# PY32F403xx register map
Vendor: PUYA Co.Ltd; Series: ARMCM4; File version: 1.2
CPU: CM4 r0p1, little endian, MPU, FPU, 4 interrupt priority bits
Registers are 32-bit, read-write, reset 0x0 unless marked. A register's access mark holds for its fields unless they carry their own. Offsets are from the block's base; [hi:lo] are bit positions; {n}, {i} and the like mark numbered series.

## EXTI
Base 0x40010400
0x00 IMR
  [18:0] MR
0x04 EMR
  [18:0] MR
0x08 RTSR
  [18:0] TR
0x0C FTSR
  [18:0] TR
0x10 SWIER
  [18:0] SWIER
0x14 PR
  [18:0] PR

## FLASH
Base 0x40022000
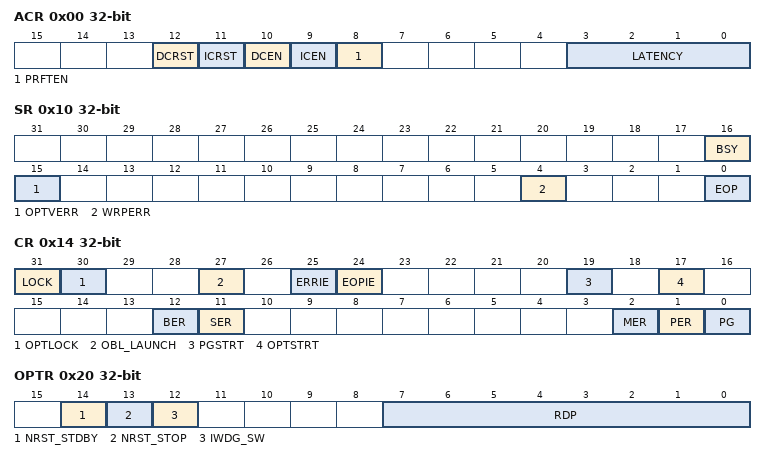
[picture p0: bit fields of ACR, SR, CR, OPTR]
0x00 ACR
  [12] DCRST
  [11] ICRST
  [10] DCEN
  [9] ICEN
  [8] PRFTEN
  [3:0] LATENCY
    1=0; 2=1; 4=2; 8=3
0x08 KEYR
  [31:0] KEY
0x0C OPTKEYR
  [31:0] OPTKEY
0x10 SR
  [16] BSY ro, [15] OPTVERR, [4] WRPERR, [0] EOP
0x14 CR
  [31] LOCK, [30] OPTLOCK, [27] OBL_LAUNCH, [25] ERRIE, [24] EOPIE, [19] PGSTRT, [17] OPTSTRT, [12] BER, [11] SER, [2] MER, [1] PER, [0] PG
0x20 OPTR
  [14] NRST_STDBY, [13] NRST_STOP, [12] IWDG_SW, [7:0] RDP
0x2C WRPR
  [11:0] WRP
    1=0; 2=1; 4=2; 8=3; 16=4; 32=5; 64=6; 128=7; 0x100=8; 0x200=9; 0x400=10; 0x800=11

## GPIOA — desc GPIO
Base 0x48000000
Same registers: GPIOB 0x48000400, GPIOC 0x48000800, GPIOD 0x48000C00, GPIOE 0x48001000
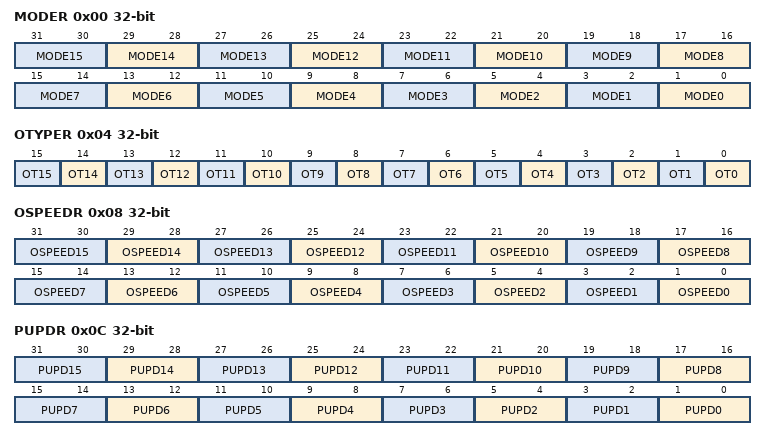
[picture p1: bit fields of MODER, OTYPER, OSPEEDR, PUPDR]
0x00 MODER
  [all] fields
    1=0; 2=1
  [2n+1:2n] MODE{n} (n=0..15)
0x04 OTYPER
  [n] OT{n} (n=0..15)
0x08 OSPEEDR
  [all] fields
    1=0; 2=1
  [2n+1:2n] OSPEED{n} (n=0..15)
0x0C PUPDR
  [all] fields
    1=0; 2=1
  [2n+1:2n] PUPD{n} (n=0..15)
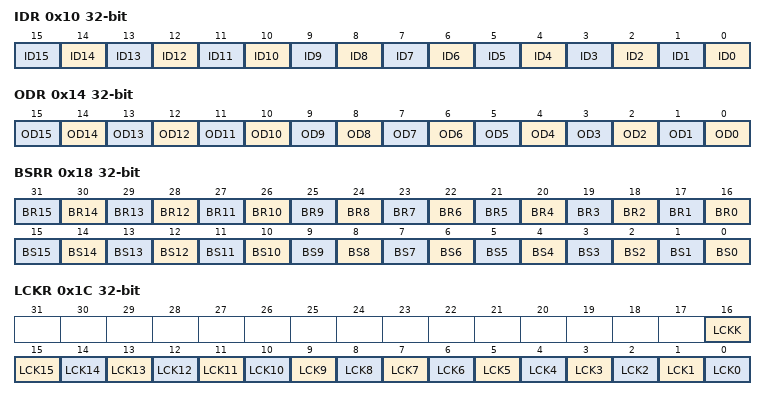
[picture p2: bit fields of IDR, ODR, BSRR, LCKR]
0x10 IDR
  [n] ID{n} ro (n=0..15)
0x14 ODR
  [n] OD{n} (n=0..15)
0x18 BSRR
  [n+16] BR{n} (n=0..15), [n] BS{n} (n=0..15)
0x1C LCKR
  [16] LCKK, [n] LCK{n} (n=0..15)
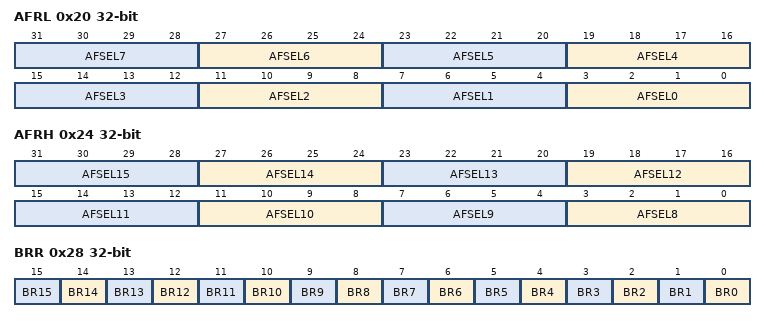
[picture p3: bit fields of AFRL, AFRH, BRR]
0x20 AFRL
  [all] fields
    1=0; 2=1; 4=2; 8=3
  [4n+3:4n] AFSEL{n} (n=0..7)
0x24 AFRH
  [all] fields
    1=0; 2=1; 4=2; 8=3
  [4n-29:4n-32] AFSEL{n} (n=8..15)
0x28 BRR
  [n] BR{n} (n=0..15)

## I2C1 — desc I2C
Base 0x40005400
Same registers: I2C2 0x40005800
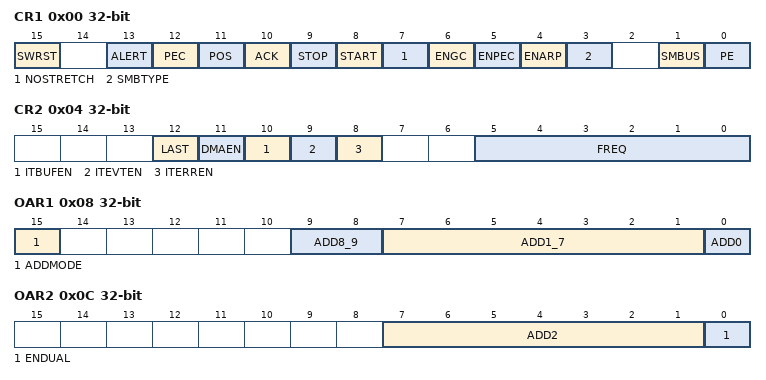
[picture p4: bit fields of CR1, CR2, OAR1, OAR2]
0x00 CR1
  [15] SWRST, [13] ALERT, [12] PEC, [11] POS, [10] ACK, [9] STOP, [8] START, [7] NOSTRETCH, [6] ENGC, [5] ENPEC, [4] ENARP, [3] SMBTYPE, [1] SMBUS, [0] PE
0x04 CR2
  [12] LAST
  [11] DMAEN
  [10] ITBUFEN
  [9] ITEVTEN
  [8] ITERREN
  [5:0] FREQ
    1=0; 2=1; 4=2; 8=3; 16=4; 32=5
0x08 OAR1
  [15] ADDMODE
  [9:8] ADD8_9 — desc ADD
  [7:1] ADD1_7 — desc ADD
  [0] ADD0
0x0C OAR2
  [7:1] ADD2, [0] ENDUAL
0x10 DR
  [7:0] DR
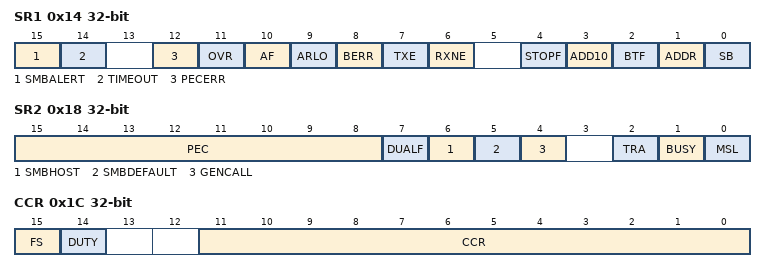
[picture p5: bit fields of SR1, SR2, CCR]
0x14 SR1
  [15] SMBALERT, [14] TIMEOUT, [12] PECERR, [11] OVR, [10] AF, [9] ARLO, [8] BERR, [7] TXE ro, [6] RXNE ro, [4] STOPF ro, [3] ADD10 ro, [2] BTF ro, [1] ADDR ro, [0] SB ro
0x18 SR2
  [15:8] PEC ro, [7] DUALF ro, [6] SMBHOST ro, [5] SMBDEFAULT ro, [4] GENCALL ro, [2] TRA ro, [1] BUSY ro, [0] MSL ro
0x1C CCR
  [15] FS, [14] DUTY, [11:0] CCR
0x20 TRISE
  [5:0] TRISE

## IWDG
Base 0x40003000
0x00 KR
  [15:0] KEY
0x04 PR
  [2:0] PR
    1=0; 2=1; 4=2
0x08 RLR
  [11:0] RL
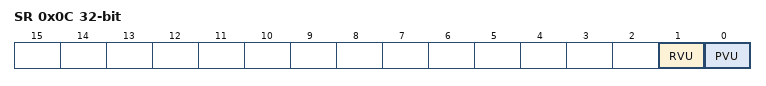
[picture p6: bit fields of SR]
0x0C SR
  [1] RVU ro, [0] PVU ro

## PWR
Base 0x40007000
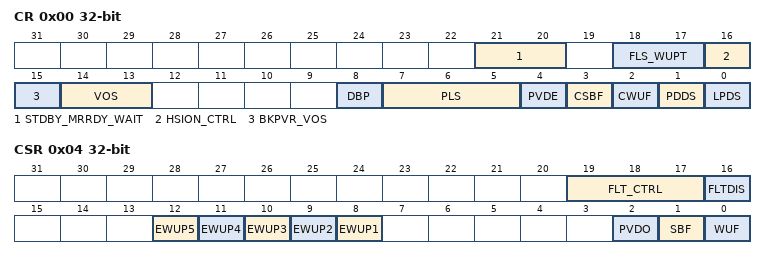
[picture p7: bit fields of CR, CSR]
0x00 CR
  [21:20] STDBY_MRRDY_WAIT
    1=0; 2=1
  [18:17] FLS_WUPT
    1=0; 2=1
  [16] HSION_CTRL
  [15] BKPVR_VOS
  [14:13] VOS
    1=0; 2=1
  [8] DBP
  [7:5] PLS
    0=1V8; 0=LEV0 (PVD level 1.8V); 1=0; 1=2V0; 1=LEV1 (PVD level 2.0V); 2=1; 2=2V2; 2=LEV2 (PVD level 2.2V); 3=2V4; 3=LEV3 (PVD level 2.4V); 4=2; 4=2V6; 4=LEV4 (PVD level 2.6V); 5=2V8; 5=LEV5 (PVD level 2.8V); 6=3V0; 6=LEV6 (PVD level 3.0V); 7=3V2; 7=LEV7 (PVD level 3.2V)
  [4] PVDE
  [3] CSBF
  [2] CWUF
  [1] PDDS
  [0] LPDS
0x04 CSR
  [19:17] FLT_CTRL
    1=0; 2=1; 4=2
  [16] FLTDIS
  [n+7] EWUP{n} (n=1..5)
  [2] PVDO ro
  [1] SBF ro
  [0] WUF ro

## RTC
Base 0x40002800
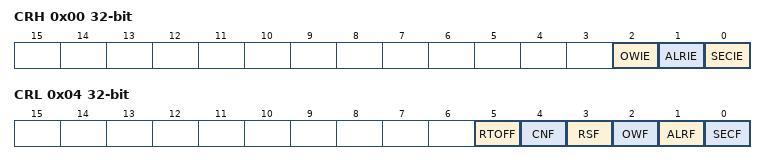
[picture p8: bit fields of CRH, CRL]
0x00 CRH
  [2] OWIE, [1] ALRIE, [0] SECIE
0x04 CRL
  [5] RTOFF ro, [4] CNF, [3] RSF, [2] OWF, [1] ALRF, [0] SECF
0x08 PRLH
  [3:0] PRL
    1=0; 2=1; 4=2; 8=3
0x0C PRLL
  [15:0] PRL
0x10 DIVH
  [15:0] DIV ro
0x14 DIVL
  [15:0] DIV ro
0x18 CNTH
  [15:0] RTC_CNT
0x1C CNTL
  [15:0] RTC_CNT
0x20 ALRH
  [15:0] RTC_ALR
0x24 ALRL
  [15:0] RTC_ALR

## SDIO
Base 0x40018000
0x00 POWER
  [0] PWRCTRL
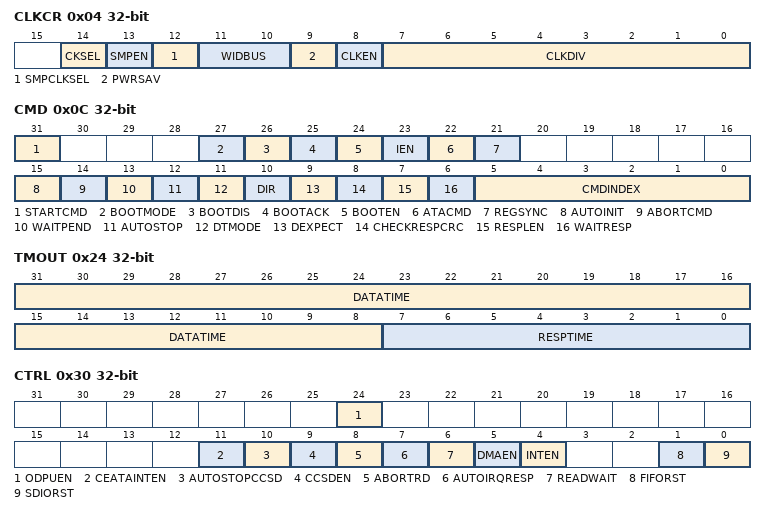
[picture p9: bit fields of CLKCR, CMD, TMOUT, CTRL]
0x04 CLKCR
  [14] CKSEL
  [13] SMPEN
  [12] SMPCLKSEL
  [11:10] WIDBUS
    1=0; 2=1
  [9] PWRSAV
  [8] CLKEN
  [7:0] CLKDIV
0x08 ARG
  [31:0] CMDARG
0x0C CMD
  [31] STARTCMD
  [27] BOOTMODE
  [26] BOOTDIS
  [25] BOOTACK
  [24] BOOTEN
  [23] IEN
  [22] ATACMD
  [21] REGSYNC
  [15] AUTOINIT
  [14] ABORTCMD
  [13] WAITPEND
  [12] AUTOSTOP
  [11] DTMODE
  [10] DIR
  [9] DEXPECT
  [8] CHECKRESPCRC
  [7] RESPLEN
  [6] WAITRESP
  [5:0] CMDINDEX
    1=0; 2=1; 4=2; 8=3; 16=4; 32=5
0x10 RESPCMD
  [5:0] RESPCMD ro
    1=0; 2=1; 4=2; 8=3; 16=4; 32=5
{0x14+4i} RESP{i} (i=0..3)
  [31:0] CARDSTATUS{i+1} ro
0x24 TMOUT
  [31:8] DATATIME, [7:0] RESPTIME
0x28 BLKSIZ
  [15:0] DBLOCKSIZE
0x2C DLEN
  [31:0] DATALENGTH
0x30 CTRL
  [24] ODPUEN, [11] CEATAINTEN, [10] AUTOSTOPCCSD, [9] CCSDEN, [8] ABORTRD, [7] AUTOIRQRESP, [6] READWAIT, [5] DMAEN, [4] INTEN, [1] FIFORST, [0] SDIORST
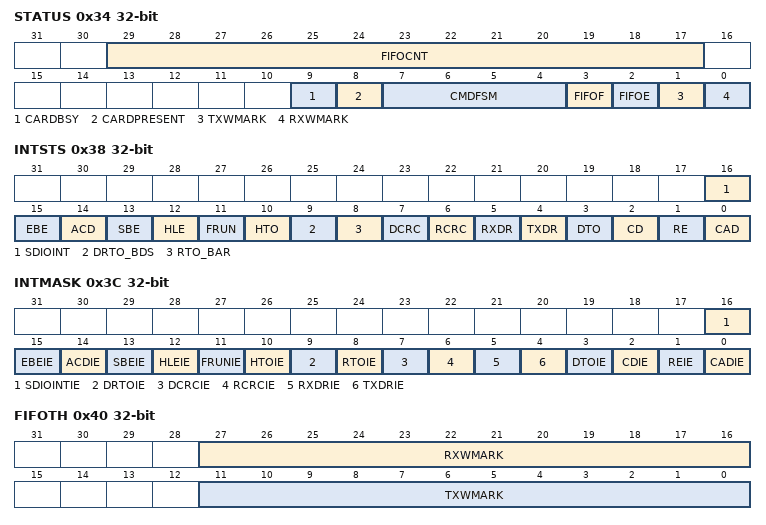
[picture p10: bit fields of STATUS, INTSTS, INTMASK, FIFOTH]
0x34 STATUS
  [29:17] FIFOCNT ro
  [9] CARDBSY ro
  [8] CARDPRESENT ro
  [7:4] CMDFSM ro
    1=0; 2=1; 4=2; 8=3
  [3] FIFOF ro
  [2] FIFOE ro
  [1] TXWMARK ro
  [0] RXWMARK ro
0x38 INTSTS
  [16] SDIOINT, [15] EBE, [14] ACD, [13] SBE, [12] HLE, [11] FRUN, [10] HTO, [9] DRTO_BDS, [8] RTO_BAR, [7] DCRC, [6] RCRC, [5] RXDR, [4] TXDR, [3] DTO, [2] CD, [1] RE, [0] CAD
0x3C INTMASK
  [16] SDIOINTIE, [15] EBEIE, [14] ACDIE, [13] SBEIE, [12] HLEIE, [11] FRUNIE, [10] HTOIE, [9] DRTOIE, [8] RTOIE, [7] DCRCIE, [6] RCRCIE, [5] RXDRIE, [4] TXDRIE, [3] DTOIE, [2] CDIE, [1] REIE, [0] CADIE
0x40 FIFOTH
  [27:16] RXWMARK, [11:0] TXWMARK
0x44 TCBCNT
  [31:0] TCBCNT ro
0x48 TBBCNT
  [31:0] TBBCNT ro
